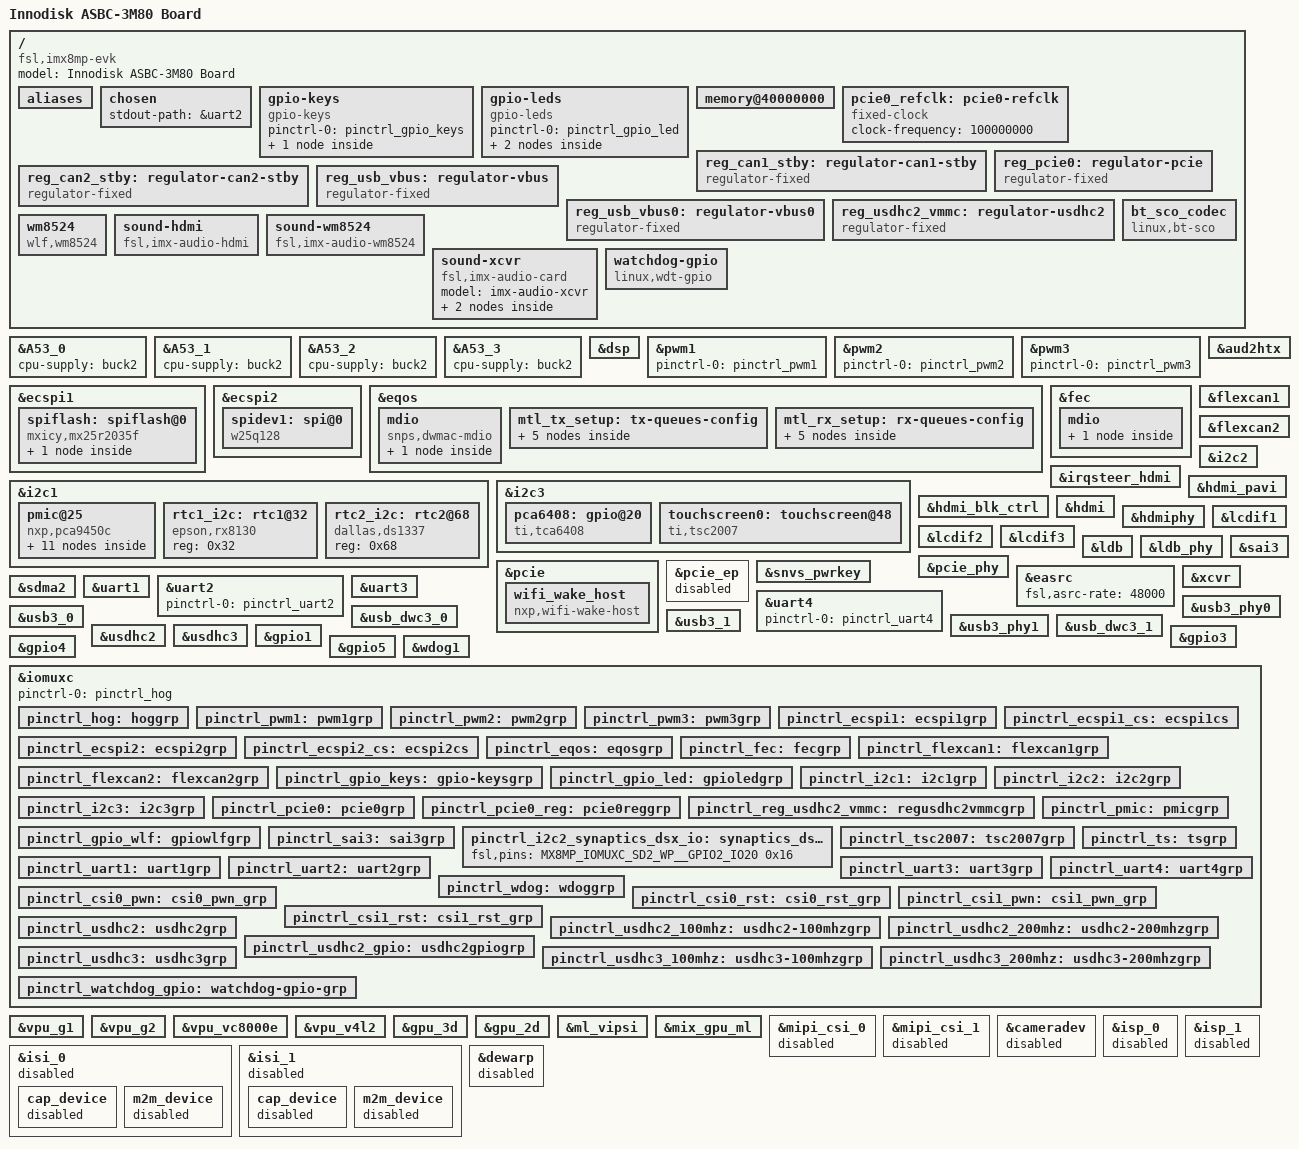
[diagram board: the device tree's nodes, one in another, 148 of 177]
// SPDX-License-Identifier: (GPL-2.0+ OR MIT)

/* Title:    Device Tree of Innodisk ASBC-3M80 Board v0.5.9
 * Author:   William Chang
 * Created:  Sep.01.2023, 09:16:15 (UTC+8)
 * Modified: May.24.2024, 15:06:37 (UTC+8)
 */

/dts-v1/;

#include <dt-bindings/phy/phy-imx8-pcie.h>
#include <dt-bindings/usb/pd.h>
#include "../freescale/imx8mp.dtsi"

/{
    model = "Innodisk ASBC-3M80 Board";
    compatible = "fsl,imx8mp-evk", "fsl,imx8mp";

    aliases {
		spi1 = &ecspi1;
		spi2 = &ecspi2;
		rtc0 = &snvs_rtc;
		rtc1 = &rtc1_i2c;
		rtc2 = &rtc2_i2c;
		pwm1 = &pwm1;
		pwm2 = &pwm2;
		pwm3 = &pwm3;
	};

    chosen {
		stdout-path = &uart2;
	};

    gpio-keys {
		compatible = "gpio-keys";
		pinctrl-names = "default";
		pinctrl-0 = <&pinctrl_gpio_keys>;

		button-user {
			label = "User Button";
			gpios = <&gpio1 7 GPIO_ACTIVE_LOW>;
			linux,code = <BTN_0>;
			wakeup-source;
		};
	};

    gpio-leds {
		compatible = "gpio-leds";
		pinctrl-names = "default";
		pinctrl-0 = <&pinctrl_gpio_led>;

		status {
			label = "yellow:status";
			gpios = <&gpio3 16 GPIO_ACTIVE_HIGH>;
			
			default-state = "on";
		};

		hdd_led {
			label = "SD/eMMC Status";
            gpios = <&gpio5 5 GPIO_ACTIVE_LOW>;
			linux,default-trigger = "mmc2";
			default-state = "off";
        };
	};

    memory@40000000 {
		device_type = "memory";
		reg = <0x0 0x40000000 0 0xc0000000>,
		      <0x1 0x00000000 0 0xc0000000>;
	};

    pcie0_refclk: pcie0-refclk {
		compatible = "fixed-clock";
		#clock-cells = <0>;
		clock-frequency = <100000000>;
	};

    reg_can1_stby: regulator-can1-stby {
		compatible = "regulator-fixed";
		regulator-name = "can1-stby";
		regulator-min-microvolt = <3300000>;
		regulator-max-microvolt = <3300000>;
		enable-active-high;
	};

    reg_can2_stby: regulator-can2-stby {
		compatible = "regulator-fixed";
		regulator-name = "can2-stby";
		regulator-min-microvolt = <3300000>;
		regulator-max-microvolt = <3300000>;
		enable-active-high;
	};

    reg_pcie0: regulator-pcie {
		compatible = "regulator-fixed";
		pinctrl-names = "default";
		pinctrl-0 = <&pinctrl_pcie0_reg>;
		regulator-name = "MPCIE_3V3";
		regulator-min-microvolt = <3300000>;
		regulator-max-microvolt = <3300000>;
		gpio = <&gpio2 2 GPIO_ACTIVE_HIGH>;
		enable-active-high;
		regulator-always-on;
	};

    reg_usb_vbus: regulator-vbus {
		compatible = "regulator-fixed";
		regulator-name = "USB_VBUS";
		regulator-min-microvolt = <5000000>;
		regulator-max-microvolt = <5000000>;
		enable-active-high;
		regulator-always-on;
	};

    reg_usb_vbus0: regulator-vbus0 {
		compatible = "regulator-fixed";
		regulator-name = "USB_VBUS_0";
		regulator-min-microvolt = <5000000>;
		regulator-max-microvolt = <5000000>;
		enable-active-high;
		regulator-always-on;
	};

    reg_usdhc2_vmmc: regulator-usdhc2 {
		compatible = "regulator-fixed";
		pinctrl-names = "default";
		pinctrl-0 = <&pinctrl_reg_usdhc2_vmmc>;
		regulator-name = "VSD_3V3";
		regulator-min-microvolt = <3300000>;
		regulator-max-microvolt = <3300000>;
		gpio = <&gpio2 19 GPIO_ACTIVE_HIGH>;
		enable-active-high;
	};

	bt_sco_codec: bt_sco_codec {
		#sound-dai-cells = <1>;
		compatible = "linux,bt-sco";
	};

    wm8524: wm8524 {
		#sound-dai-cells = <0>;
		compatible = "wlf,wm8524";
		pinctrl-names = "default";
		pinctrl-0 = <&pinctrl_gpio_wlf>;
		wlf,mute-gpios = <&gpio2 7 GPIO_ACTIVE_LOW>; /*Work only with low*/
		clocks = <&clk IMX8MP_CLK_SAI3_ROOT>;
		clock-names = "mclk";
		status = "okay";
	};

    sound-hdmi {
		compatible = "fsl,imx-audio-hdmi";
		model = "audio-hdmi";
		audio-cpu = <&aud2htx>;
		hdmi-out;
		constraint-rate = <44100>,
				<88200>,
				<176400>,
				<32000>,
				<48000>,
				<96000>,
				<192000>;
		status = "okay";
	};

    sound-wm8524 {
		compatible = "fsl,imx-audio-wm8524";
		model = "wm8524-audio";
		audio-cpu = <&sai3>;
		audio-codec = <&wm8524>;
		audio-asrc=	<&easrc>;
		audio-routing =
			"Line Out Jack", "LINEVOUTL",
			"Line Out Jack", "LINEVOUTR";
	};

    sound-xcvr {
		compatible = "fsl,imx-audio-card";
		model = "imx-audio-xcvr";
		pri-dai-link {
			link-name = "XCVR PCM";
			cpu {
				sound-dai = <&xcvr>;
			};
		};
	};

    watchdog-gpio {
		/* TPS3431 */
		pinctrl-names = "default";
		pinctrl-0 = <&pinctrl_watchdog_gpio>;
		compatible = "linux,wdt-gpio";
		// pwms = <&pwm1 0 10 0>;
		always-running;
		gpios =	<&gpio1 5 GPIO_ACTIVE_HIGH>;
		hw_algo = "toggle";
		/* Reset triggers in 2..3 seconds */
		hw_margin_ms = <200>;
		/* Disabled by default */
		status = "okay";
	};
};

&A53_0 {
	cpu-supply = <&buck2>;
};

&A53_1 {
	cpu-supply = <&buck2>;
};

&A53_2 {
	cpu-supply = <&buck2>;
};

&A53_3 {
	cpu-supply = <&buck2>;
};

&dsp {
	status = "okay";
};

&pwm1 {
	pinctrl-names = "default";
	pinctrl-0 = <&pinctrl_pwm1>;
	status = "okay";
};

&pwm2 {
	pinctrl-names = "default";
	pinctrl-0 = <&pinctrl_pwm2>;
	status = "okay";
};

&pwm3 {
	pinctrl-names = "default";
	pinctrl-0 = <&pinctrl_pwm3>;
	status = "okay";
};

&aud2htx {
	status = "okay";
};

&ecspi1 {
	pinctrl-names = "default";
	pinctrl-0 = <&pinctrl_ecspi1 &pinctrl_ecspi1_cs>;
	cs-gpios = <&gpio5 9 GPIO_ACTIVE_LOW>;
	status = "okay";

	spiflash: spiflash@0 {
		#address-cells = <1>;
		#size-cells = <1>;
		compatible = "mxicy,mx25r2035f", "jedec,spi-nor";
		spi-max-frequency = <50000000>;
		reg = <0>;
		mode = <1>;

		partition@0{
			reg = <0x0 0x100000>;
			label = "spi-flash";
		};
	};
};

&ecspi2 {
	fsl,spi-num-chipselects = <0>;
	pinctrl-names = "default";
	pinctrl-0 = <&pinctrl_ecspi2 &pinctrl_ecspi2_cs>;
	cs-gpios = <&gpio5 13 GPIO_ACTIVE_LOW>;
	status = "okay";

	spidev1: spi@0 {
		#address-cells = <1>;
		#size-cells = <0>;
		reg = <0>;
		compatible = "w25q128", "jedec,spi-nor";
		spi-max-frequency = <500000>;
		mode = <1>;
	};
};

&eqos {
	pinctrl-names = "default";
	pinctrl-0 = <&pinctrl_eqos>;
	phy-mode = "rgmii-id";
	phy-handle = <&ethphy0>;
	snps,force_thresh_dma_mode;
	snps,mtl-tx-config = <&mtl_tx_setup>;
	snps,mtl-rx-config = <&mtl_rx_setup>;
	status = "okay";

	mdio {
		compatible = "snps,dwmac-mdio";
		#address-cells = <1>;
		#size-cells = <0>;

		ethphy0: ethernet-phy@1 {
			compatible = "ethernet-phy-ieee802.3-c22";
			reg = <1>;
			eee-broken-1000t;
			reset-gpios = <&gpio4 22 GPIO_ACTIVE_LOW>;
			reset-assert-us = <10000>;
			reset-deassert-us = <80000>;
			realtek,clkout-disable;
		};
	};

	mtl_tx_setup: tx-queues-config {
		snps,tx-queues-to-use = <5>;
		snps,tx-sched-sp;

		queue0 {
			snps,dcb-algorithm;
			snps,priority = <0x1>;
		};

		queue1 {
			snps,dcb-algorithm;
			snps,priority = <0x2>;
		};

		queue2 {
			snps,dcb-algorithm;
			snps,priority = <0x4>;
		};

		queue3 {
			snps,dcb-algorithm;
			snps,priority = <0x8>;
		};

		queue4 {
			snps,dcb-algorithm;
			snps,priority = <0xf0>;
		};
	};

	mtl_rx_setup: rx-queues-config {
		snps,rx-queues-to-use = <5>;
		snps,rx-sched-sp;

		queue0 {
			snps,dcb-algorithm;
			snps,priority = <0x1>;
			snps,map-to-dma-channel = <0>;
		};

		queue1 {
			snps,dcb-algorithm;
			snps,priority = <0x2>;
			snps,map-to-dma-channel = <1>;
		};

		queue2 {
			snps,dcb-algorithm;
			snps,priority = <0x4>;
			snps,map-to-dma-channel = <2>;
		};

		queue3 {
			snps,dcb-algorithm;
			snps,priority = <0x8>;
			snps,map-to-dma-channel = <3>;
		};

		queue4 {
			snps,dcb-algorithm;
			snps,priority = <0xf0>;
			snps,map-to-dma-channel = <4>;
		};
	};
};

&fec {
	pinctrl-names = "default";
	pinctrl-0 = <&pinctrl_fec>;
	phy-mode = "rgmii-id";
	phy-handle = <&ethphy1>;
	fsl,magic-packet;
	status = "okay";

	mdio {
		#address-cells = <1>;
		#size-cells = <0>;

		ethphy1: ethernet-phy@1 {
			compatible = "ethernet-phy-ieee802.3-c22";
			reg = <1>;
			eee-broken-1000t;
			reset-gpios = <&gpio4 2 GPIO_ACTIVE_LOW>;
			reset-assert-us = <10000>;
			reset-deassert-us = <80000>;
			realtek,aldps-enable;
			realtek,clkout-disable;
		};
	};
};

&flexcan1 {
	pinctrl-names = "default";
	pinctrl-0 = <&pinctrl_flexcan1>;
	xceiver-supply = <&reg_can1_stby>;
	status = "okay";
};

&flexcan2 {
	pinctrl-names = "default";
	pinctrl-0 = <&pinctrl_flexcan2>;
	xceiver-supply = <&reg_can2_stby>;
	status = "okay";/* can2 pin conflict with pdm */
};

&i2c1 {
	clock-frequency = <400000>;
	pinctrl-names = "default";
	pinctrl-0 = <&pinctrl_i2c1>;
	status = "okay";

	pmic@25 {
		compatible = "nxp,pca9450c";
		reg = <0x25>;
		pinctrl-names = "default";
		pinctrl-0 = <&pinctrl_pmic>;
		interrupt-parent = <&gpio1>;
		interrupts = <3 IRQ_TYPE_LEVEL_LOW>;

		regulators {
			buck1: BUCK1 {
				regulator-name = "BUCK1";
				regulator-min-microvolt = <600000>;
				regulator-max-microvolt = <2187500>;
				regulator-boot-on;
				regulator-always-on;
				regulator-ramp-delay = <3125>;
			};

			buck2: BUCK2 {
				regulator-name = "BUCK2";
				regulator-min-microvolt = <600000>;
				regulator-max-microvolt = <2187500>;
				regulator-boot-on;
				regulator-always-on;
				regulator-ramp-delay = <3125>;
				nxp,dvs-run-voltage = <950000>;
				nxp,dvs-standby-voltage = <850000>;
			};

			buck4: BUCK4{
				regulator-name = "BUCK4";
				regulator-min-microvolt = <600000>;
				regulator-max-microvolt = <3400000>;
				regulator-boot-on;
				regulator-always-on;
			};

			buck5: BUCK5{
				regulator-name = "BUCK5";
				regulator-min-microvolt = <600000>;
				regulator-max-microvolt = <3400000>;
				regulator-boot-on;
				regulator-always-on;
			};

			buck6: BUCK6 {
				regulator-name = "BUCK6";
				regulator-min-microvolt = <600000>;
				regulator-max-microvolt = <3400000>;
				regulator-boot-on;
				regulator-always-on;
			};

			ldo1: LDO1 {
				regulator-name = "LDO1";
				regulator-min-microvolt = <1600000>;
				regulator-max-microvolt = <3300000>;
				regulator-boot-on;
				regulator-always-on;
			};

			ldo2: LDO2 {
				regulator-name = "LDO2";
				regulator-min-microvolt = <800000>;
				regulator-max-microvolt = <1150000>;
				regulator-boot-on;
				regulator-always-on;
			};

			ldo3: LDO3 {
				regulator-name = "LDO3";
				regulator-min-microvolt = <800000>;
				regulator-max-microvolt = <3300000>;
				regulator-boot-on;
				regulator-always-on;
			};

			ldo4: LDO4 {
				regulator-name = "LDO4";
				regulator-min-microvolt = <800000>;
				regulator-max-microvolt = <3300000>;
				regulator-boot-on;
				regulator-always-on;
			};

			ldo5: LDO5 {
				regulator-name = "LDO5";
				regulator-min-microvolt = <1800000>;
				regulator-max-microvolt = <3300000>;
				regulator-boot-on;
				regulator-always-on;
			};
		};
	};

    rtc1_i2c: rtc1@32 {
		compatible = "epson,rx8130";
		reg = <0x32>;
	};

	rtc2_i2c: rtc2@68 {
		compatible = "dallas,ds1337";
		reg = <0x68>;
	};
};

&i2c2 {
	clock-frequency = <100000>;
	pinctrl-names = "default";
	pinctrl-0 = <&pinctrl_i2c2>;
	status = "okay";
};

&i2c3 {
	clock-frequency = <400000>;
	pinctrl-names = "default";
	pinctrl-0 = <&pinctrl_i2c3>;
	status = "okay";

	pca6408: gpio@20 {
		compatible = "ti,tca6408";
		reg = <0x20>;
		gpio-controller;
		#gpio-cells = <2>;
		gpio-line-names = "I2C_GPIO0",
			"I2C_GPIO1",
			"I2C_GPIO2",
			"I2C_GPIO3",
			"I2C_GPIO4",
			"I2C_GPIO5",
			"I2C_GPIO6",
			"I2C_GPIO7";
	};

    touchscreen0: touchscreen@48 {
		compatible = "ti,tsc2007";
		reg = <0x48>;
		pinctrl-names = "default";
		pinctrl-0 = <&pinctrl_tsc2007>;
		interrupt-parent = <&gpio1>;
		interrupts = <6 IRQ_TYPE_EDGE_FALLING>;
		gpios = <&gpio1 6 GPIO_ACTIVE_LOW>;
		ti,x-plate-ohms = <500>;
		wakeup-source;
		status = "okay";
	};

    /* Uncomment this part for enabling the capacitive touch panel */

	// touchscreen1: touchscreen@2a {
	// 	compatible = "eeti,exc80h60";
	// 	pinctrl-names = "default";
	// 	pinctrl-0 = <&pinctrl_ts>;
	// 	reg = <0x2a>;
	// 	interrupt-parent = <&gpio4>;
	// 	interrupts = <0 IRQ_TYPE_EDGE_FALLING>;
	// 	reset-gpio = <&gpio4 1 GPIO_ACTIVE_LOW>;
	// 	status = "okay";
	// };
};

&irqsteer_hdmi {
	status = "okay";
};

&hdmi_blk_ctrl {
	status = "okay";
};

&hdmi_pavi {
	status = "okay";
};

&hdmi {
	status = "okay";
};

&hdmiphy {
	status = "okay";
};

&lcdif1 {
	status = "okay";
};

&lcdif2 {
	status = "okay";
};

&lcdif3 {
	status = "okay";

	thres-low  = <1 2>;             /* (FIFO * 1 / 2) */
	thres-high = <3 4>;             /* (FIFO * 3 / 4) */
};

&ldb {
	status = "okay";
};

&ldb_phy {
	status = "okay";
};

&pcie_phy {
	fsl,refclk-pad-mode = <IMX8_PCIE_REFCLK_PAD_INPUT>;
	clocks = <&pcie0_refclk>;
	clock-names = "ref";
	status = "okay";
};

&pcie {
	pinctrl-names = "default";
	pinctrl-0 = <&pinctrl_pcie0>;
	reset-gpio = <&gpio3 1 GPIO_ACTIVE_LOW>;
	clocks = <&clk IMX8MP_CLK_HSIO_ROOT>,
		 <&clk IMX8MP_CLK_PCIE_ROOT>,
		 <&clk IMX8MP_CLK_HSIO_AXI>;
	clock-names = "pcie", "pcie_aux", "pcie_bus";
	assigned-clocks = <&clk IMX8MP_CLK_PCIE_AUX>;
	assigned-clock-rates = <10000000>;
	assigned-clock-parents = <&clk IMX8MP_SYS_PLL2_50M>;
	vpcie-supply = <&reg_pcie0>;
	fsl,max-link-speed = <3>;
	status = "okay";

	wifi_wake_host {
		compatible = "nxp,wifi-wake-host";
		interrupt-parent = <&gpio5>;
		interrupts = <21 IRQ_TYPE_LEVEL_LOW>;
		interrupt-names = "host-wake";
	};
};

&pcie_ep{
	pinctrl-names = "default";
	pinctrl-0 = <&pinctrl_pcie0>;
	clocks = <&clk IMX8MP_CLK_HSIO_ROOT>,
		 <&clk IMX8MP_CLK_PCIE_ROOT>,
		 <&clk IMX8MP_CLK_HSIO_AXI>;
	clock-names = "pcie", "pcie_aux", "pcie_bus";
	assigned-clocks = <&clk IMX8MP_CLK_HSIO_AXI>,
			  <&clk IMX8MP_CLK_PCIE_AUX>;
	assigned-clock-rates = <500000000>, <10000000>;
	assigned-clock-parents = <&clk IMX8MP_SYS_PLL2_500M>,
				 <&clk IMX8MP_SYS_PLL2_50M>;
	status = "disabled";
};

&snvs_pwrkey {
	status = "okay";
};

&easrc {
	#sound-dai-cells = <0>;
	fsl,asrc-rate  = <48000>;
	status = "okay";
};

&sai3 {
	#sound-dai-cells = <0>;
	pinctrl-names = "default";
	pinctrl-0 = <&pinctrl_sai3>;
	assigned-clocks = <&clk IMX8MP_CLK_SAI3>;
	assigned-clock-parents = <&clk IMX8MP_AUDIO_PLL1_OUT>;
	assigned-clock-rates = <24576000>;
	fsl,sai-mclk-direction-output;
	fsl,sai-asynchronous;
	status = "okay";
};

&xcvr {
	#sound-dai-cells = <0>;
	status = "okay";
};

&sdma2 {
	status = "okay";
};

&uart1 {
	pinctrl-names = "default";
	pinctrl-0 = <&pinctrl_uart1>;
	assigned-clocks = <&clk IMX8MP_CLK_UART1>;
	assigned-clock-parents = <&clk IMX8MP_SYS_PLL1_80M>;
	fsl,uart-has-rtscts;
	status = "okay";
};

&uart2 {
	/* console */
	pinctrl-names = "default";
	pinctrl-0 = <&pinctrl_uart2>;
	status = "okay";
};

&uart3 {
	pinctrl-names = "default";
	pinctrl-0 = <&pinctrl_uart3>;
	assigned-clocks = <&clk IMX8MP_CLK_UART3>;
	assigned-clock-parents = <&clk IMX8MP_SYS_PLL1_80M>;
	fsl,uart-has-rtscts;
	status = "okay";
};

&uart4 {
	/* console */
	pinctrl-names = "default";
	pinctrl-0 = <&pinctrl_uart4>;
	status = "okay";
};

&usb3_phy0 {
	fsl,phy-tx-vref-tune = <0xe>;
	fsl,phy-tx-preemp-amp-tune = <3>;
	fsl,phy-tx-vboost-level = <2>;
	fsl,phy-comp-dis-tune = <7>;
	fsl,pcs-tx-deemph-3p5db = <0x21>;
	fsl,phy-pcs-tx-swing-full = <0x7f>;
	status = "okay";
};

&usb3_0 {
	status = "okay";
};

&usb_dwc3_0 {
    vbus-supply = <&reg_usb_vbus0>;
	dr_mode = "host";
	status = "okay";
};

&usb3_phy1 {
	fsl,phy-tx-preemp-amp-tune = <3>;
	fsl,phy-tx-vref-tune = <0xb>;
	fsl,phy-tx-vboost-level = <2>;
	status = "okay";
};

&usb3_1 {
	status = "okay";
};

&usb_dwc3_1 {
	vbus-supply = <&reg_usb_vbus>;
	dr_mode = "host";
	status = "okay";
};

&usdhc2 {
	assigned-clocks = <&clk IMX8MP_CLK_USDHC2>;
	assigned-clock-rates = <400000000>;
	pinctrl-names = "default", "state_100mhz", "state_200mhz";
	pinctrl-0 = <&pinctrl_usdhc2>, <&pinctrl_usdhc2_gpio>;
	pinctrl-1 = <&pinctrl_usdhc2_100mhz>, <&pinctrl_usdhc2_gpio>;
	pinctrl-2 = <&pinctrl_usdhc2_200mhz>, <&pinctrl_usdhc2_gpio>;
	cd-gpios = <&gpio2 12 GPIO_ACTIVE_LOW>;
	vmmc-supply = <&reg_usdhc2_vmmc>;
	bus-width = <4>;
	status = "okay";
};

&usdhc3 {
	assigned-clocks = <&clk IMX8MP_CLK_USDHC3>;
	assigned-clock-rates = <400000000>;
	pinctrl-names = "default", "state_100mhz", "state_200mhz";
	pinctrl-0 = <&pinctrl_usdhc3>;
	pinctrl-1 = <&pinctrl_usdhc3_100mhz>;
	pinctrl-2 = <&pinctrl_usdhc3_200mhz>;
	bus-width = <8>;
	non-removable;
	status = "okay";
};
&gpio1 {
	gpio-line-names = "WDOG_SET", "", "", "",
			  "", "WDOG_EN", "", "User_Button",
			  "EXP_GPIO3", "", "", "",
			  "", "", "EXP_GPIO8", "EXP_GPIO9",
			  "", "", "", "",
			  "", "", "", "",
			  "", "", "", "",
			  "", "", "", "";
};

&gpio3 {
	gpio-line-names = "", "", "", "",
			  "", "", "", "",
			  "", "", "", "",
			  "", "", "", "",
			  "", "", "", "",
			  "", "EXP_GPIO4", "EXP_GPIO5", "EXP_GPIO6",
			  "EXP_GPIO7", "", "", "",
			  "", "", "", "";
};

&gpio4 {
	gpio-line-names = "", "", "", "",
			  "", "", "", "",
			  "", "", "", "",
			  "", "", "", "",
			  "", "", "", "",
			  "", "", "", "EXP_GPIO2",
			  "EXP_GPIO0", "EXP_GPIO1", "", "",
			  "", "", "EXP_GPIO10", "";
};

&gpio5 {
	gpio-line-names = "", "", "", "",
			  "", "", "", "",
			  "", "", "", "",
			  "", "", "", "",
			  "", "", "", "",
			  "", "", "", "",
			  "EXP_GPIO11", "", "", "",
			  "", "", "", "";
	
	gpios = <&gpio5 24 GPIO_ACTIVE_HIGH>;
	enable-active-high;
};

&wdog1 {
	pinctrl-names = "default";
	pinctrl-0 = <&pinctrl_wdog>;
	fsl,ext-reset-output;
	status = "okay";
};

&iomuxc {
	pinctrl-names = "default";
	pinctrl-0 = <&pinctrl_hog>;
	pinctrl_hog: hoggrp {
		fsl,pins = <
			MX8MP_IOMUXC_HDMI_DDC_SCL__HDMIMIX_HDMI_SCL	0x400001c2
			MX8MP_IOMUXC_HDMI_DDC_SDA__HDMIMIX_HDMI_SDA	0x400001c2
			MX8MP_IOMUXC_HDMI_HPD__HDMIMIX_HDMI_HPD		0x40000010
			MX8MP_IOMUXC_HDMI_CEC__HDMIMIX_HDMI_CEC		0x40000010			
		>;
	};
    pinctrl_pwm1: pwm1grp {
		fsl,pins = <
			MX8MP_IOMUXC_GPIO1_IO01__PWM1_OUT	0x116
		>;
	};

	pinctrl_pwm2: pwm2grp {
		fsl,pins = <
			MX8MP_IOMUXC_GPIO1_IO09__PWM2_OUT		0x116
		>;
	};

    pinctrl_pwm3: pwm3grp {
		fsl,pins = <
			MX8MP_IOMUXC_GPIO1_IO10__PWM3_OUT		0x116
		>;
	};

    pinctrl_ecspi1: ecspi1grp {
		fsl,pins = <
			MX8MP_IOMUXC_ECSPI1_SCLK__ECSPI1_SCLK		0x10
			MX8MP_IOMUXC_ECSPI1_MOSI__ECSPI1_MOSI		0x10
			MX8MP_IOMUXC_ECSPI1_MISO__ECSPI1_MISO		0x10
		>;
	};

	pinctrl_ecspi1_cs: ecspi1cs {
		fsl,pins = <
			MX8MP_IOMUXC_ECSPI1_SS0__GPIO5_IO09			0x10
		>;
	};

	pinctrl_ecspi2: ecspi2grp {
		fsl,pins = <
			MX8MP_IOMUXC_ECSPI2_SCLK__ECSPI2_SCLK		0x82
			MX8MP_IOMUXC_ECSPI2_MOSI__ECSPI2_MOSI		0x82
			MX8MP_IOMUXC_ECSPI2_MISO__ECSPI2_MISO		0x82
		>;
	};

	pinctrl_ecspi2_cs: ecspi2cs {
		fsl,pins = <
			MX8MP_IOMUXC_ECSPI2_SS0__GPIO5_IO13		0x40000
		>;
	};

    pinctrl_eqos: eqosgrp {
		fsl,pins = <
			MX8MP_IOMUXC_ENET_MDC__ENET_QOS_MDC				0x2
			MX8MP_IOMUXC_ENET_MDIO__ENET_QOS_MDIO				0x2
			MX8MP_IOMUXC_ENET_RD0__ENET_QOS_RGMII_RD0			0x90
			MX8MP_IOMUXC_ENET_RD1__ENET_QOS_RGMII_RD1			0x90
			MX8MP_IOMUXC_ENET_RD2__ENET_QOS_RGMII_RD2			0x90
			MX8MP_IOMUXC_ENET_RD3__ENET_QOS_RGMII_RD3			0x90
			MX8MP_IOMUXC_ENET_RXC__CCM_ENET_QOS_CLOCK_GENERATE_RX_CLK	0x90
			MX8MP_IOMUXC_ENET_RX_CTL__ENET_QOS_RGMII_RX_CTL			0x90
			MX8MP_IOMUXC_ENET_TD0__ENET_QOS_RGMII_TD0			0x16
			MX8MP_IOMUXC_ENET_TD1__ENET_QOS_RGMII_TD1			0x16
			MX8MP_IOMUXC_ENET_TD2__ENET_QOS_RGMII_TD2			0x16
			MX8MP_IOMUXC_ENET_TD3__ENET_QOS_RGMII_TD3			0x16
			MX8MP_IOMUXC_ENET_TX_CTL__ENET_QOS_RGMII_TX_CTL			0x16
			MX8MP_IOMUXC_ENET_TXC__CCM_ENET_QOS_CLOCK_GENERATE_TX_CLK	0x16
			MX8MP_IOMUXC_SAI2_RXC__GPIO4_IO22				0x10
		>;
	};

	pinctrl_fec: fecgrp {
		fsl,pins = <
			MX8MP_IOMUXC_SAI1_RXD2__ENET1_MDC		0x2
			MX8MP_IOMUXC_SAI1_RXD3__ENET1_MDIO		0x2
			MX8MP_IOMUXC_SAI1_RXD4__ENET1_RGMII_RD0		0x90
			MX8MP_IOMUXC_SAI1_RXD5__ENET1_RGMII_RD1		0x90
			MX8MP_IOMUXC_SAI1_RXD6__ENET1_RGMII_RD2		0x90
			MX8MP_IOMUXC_SAI1_RXD7__ENET1_RGMII_RD3		0x90
			MX8MP_IOMUXC_SAI1_TXC__ENET1_RGMII_RXC		0x90
			MX8MP_IOMUXC_SAI1_TXFS__ENET1_RGMII_RX_CTL	0x90
			MX8MP_IOMUXC_SAI1_TXD0__ENET1_RGMII_TD0		0x16
			MX8MP_IOMUXC_SAI1_TXD1__ENET1_RGMII_TD1		0x16
			MX8MP_IOMUXC_SAI1_TXD2__ENET1_RGMII_TD2		0x16
			MX8MP_IOMUXC_SAI1_TXD3__ENET1_RGMII_TD3		0x16
			MX8MP_IOMUXC_SAI1_TXD4__ENET1_RGMII_TX_CTL	0x16
			MX8MP_IOMUXC_SAI1_TXD5__ENET1_RGMII_TXC		0x16
			MX8MP_IOMUXC_SAI1_RXD0__GPIO4_IO02		0x10
		>;
	};

    pinctrl_flexcan1: flexcan1grp {
		fsl,pins = <
			MX8MP_IOMUXC_SPDIF_RX__CAN1_RX          0x154
			MX8MP_IOMUXC_SPDIF_TX__CAN1_TX          0x154
		>;
	};

    pinctrl_flexcan2: flexcan2grp {
		fsl,pins = <
			MX8MP_IOMUXC_SAI2_TXD0__CAN2_TX        		0x154
			MX8MP_IOMUXC_SAI2_MCLK__CAN2_RX        		0x154
		>;
	};

    pinctrl_gpio_keys: gpio-keysgrp {
		fsl,pins = <
			MX8MP_IOMUXC_GPIO1_IO07__GPIO1_IO07 		0x140
		>;
	};

    pinctrl_gpio_led: gpioledgrp {
		fsl,pins = <
			MX8MP_IOMUXC_NAND_READY_B__GPIO3_IO16	0x140
		>;
	};

    pinctrl_i2c1: i2c1grp {
		fsl,pins = <
			MX8MP_IOMUXC_I2C1_SCL__I2C1_SCL		0x400001c2
			MX8MP_IOMUXC_I2C1_SDA__I2C1_SDA		0x400001c2
		>;
	};

	pinctrl_i2c2: i2c2grp {
		fsl,pins = <
			MX8MP_IOMUXC_I2C2_SCL__I2C2_SCL		0x400001c2
			MX8MP_IOMUXC_I2C2_SDA__I2C2_SDA		0x400001c2
		>;
	};

	pinctrl_i2c3: i2c3grp {
		fsl,pins = <
			MX8MP_IOMUXC_I2C3_SCL__I2C3_SCL		0x400001c2
			MX8MP_IOMUXC_I2C3_SDA__I2C3_SDA		0x400001c2
		>;
	};

    pinctrl_pcie0: pcie0grp {
		fsl,pins = <
			MX8MP_IOMUXC_I2C4_SCL__PCIE_CLKREQ_B	0x60 /* open drain, pull up */
            MX8MP_IOMUXC_NAND_CE0_B__GPIO3_IO01		0x1c0
			MX8MP_IOMUXC_I2C4_SDA__GPIO5_IO21		0x1c4
		>;
	};

    pinctrl_pcie0_reg: pcie0reggrp {
		fsl,pins = <
			MX8MP_IOMUXC_SD1_DATA0__GPIO2_IO02	0x40
		>;
	};

    pinctrl_reg_usdhc2_vmmc: regusdhc2vmmcgrp {
		fsl,pins = <
			MX8MP_IOMUXC_SD2_RESET_B__GPIO2_IO19	0x40
		>;
	};

    pinctrl_pmic: pmicgrp {
		fsl,pins = <
			MX8MP_IOMUXC_GPIO1_IO03__GPIO1_IO03	0x000001c0
		>;
	};

	pinctrl_gpio_wlf: gpiowlfgrp {
		fsl,pins = <
			MX8MP_IOMUXC_SD1_DATA5__GPIO2_IO07				0xd6
		>;
	};

    pinctrl_sai3: sai3grp {
		fsl,pins = <
			MX8MP_IOMUXC_SAI3_TXFS__AUDIOMIX_SAI3_TX_SYNC	0xd6
			MX8MP_IOMUXC_SAI3_TXC__AUDIOMIX_SAI3_TX_BCLK	0xd6
			MX8MP_IOMUXC_SAI3_TXD__AUDIOMIX_SAI3_TX_DATA00	0xd6
			MX8MP_IOMUXC_SAI3_MCLK__AUDIOMIX_SAI3_MCLK		0xd6
		>;
	};

    pinctrl_i2c2_synaptics_dsx_io: synaptics_dsx_iogrp {
		fsl,pins = <
			MX8MP_IOMUXC_SD2_WP__GPIO2_IO20		0x16
		>;
	};

	pinctrl_tsc2007: tsc2007grp {
		fsl,pins = <
		MX8MP_IOMUXC_GPIO1_IO06__GPIO1_IO06 0x10 /* Interrupt */
		>;
  	};

	pinctrl_ts: tsgrp {
		fsl,pins = <
			MX8MP_IOMUXC_SAI1_RXFS__GPIO4_IO00		0x16
			MX8MP_IOMUXC_SAI1_RXC__GPIO4_IO01 		0x10
		>;
	};

    pinctrl_uart1: uart1grp {
		fsl,pins = <
			MX8MP_IOMUXC_UART1_RXD__UART1_DCE_RX	0x140
			MX8MP_IOMUXC_UART1_TXD__UART1_DCE_TX	0x140
			MX8MP_IOMUXC_UART3_RXD__UART1_DCE_CTS	0x140
			MX8MP_IOMUXC_UART3_TXD__UART1_DCE_RTS	0x140
		>;
	};

	pinctrl_uart2: uart2grp {
		fsl,pins = <
			MX8MP_IOMUXC_SD1_DATA3__UART2_DCE_RX	0x140
			MX8MP_IOMUXC_SD1_DATA2__UART2_DCE_TX	0x140
		>;
	};

	pinctrl_uart3: uart3grp {
		fsl,pins = <
			MX8MP_IOMUXC_SD1_DATA6__UART3_DCE_TX		0x140
			MX8MP_IOMUXC_SD1_DATA7__UART3_DCE_RX 		0x140
			MX8MP_IOMUXC_SD1_RESET_B__UART3_DCE_RTS		0x140
			MX8MP_IOMUXC_SD1_STROBE__UART3_DCE_CTS		0x140
		>;
	};

    pinctrl_uart4: uart4grp {
		fsl,pins = <
			MX8MP_IOMUXC_UART4_RXD__UART4_DCE_RX	0x140
			MX8MP_IOMUXC_UART4_TXD__UART4_DCE_TX	0x140
		>;
	};

	pinctrl_wdog: wdoggrp {
		fsl,pins = <
			MX8MP_IOMUXC_GPIO1_IO02__WDOG1_WDOG_B	0x166
		>;
	};
	
	pinctrl_csi0_pwn: csi0_pwn_grp {
		fsl,pins = <
			MX8MP_IOMUXC_SAI1_TXD6__GPIO4_IO18		0x10
		>;
	};

	pinctrl_csi0_rst: csi0_rst_grp {
		fsl,pins = <	
			MX8MP_IOMUXC_SAI1_TXD7__GPIO4_IO19		0x10
		>;
	};

	pinctrl_csi1_pwn: csi1_pwn_grp {
		fsl,pins = <
			MX8MP_IOMUXC_SAI3_RXFS__GPIO4_IO28		0x10
		>;
	};

	pinctrl_csi1_rst: csi1_rst_grp {
		fsl,pins = <
			MX8MP_IOMUXC_SAI3_RXC__GPIO4_IO29		0x10
		>;
	};

    pinctrl_usdhc2: usdhc2grp {
		fsl,pins = <
			MX8MP_IOMUXC_SD2_CLK__USDHC2_CLK	0x190
			MX8MP_IOMUXC_SD2_CMD__USDHC2_CMD	0x1d0
			MX8MP_IOMUXC_SD2_DATA0__USDHC2_DATA0	0x1d0
			MX8MP_IOMUXC_SD2_DATA1__USDHC2_DATA1	0x1d0
			MX8MP_IOMUXC_SD2_DATA2__USDHC2_DATA2	0x1d0
			MX8MP_IOMUXC_SD2_DATA3__USDHC2_DATA3	0x1d0
			MX8MP_IOMUXC_GPIO1_IO04__USDHC2_VSELECT	0xc0
		>;
	};

	pinctrl_usdhc2_100mhz: usdhc2-100mhzgrp {
		fsl,pins = <
			MX8MP_IOMUXC_SD2_CLK__USDHC2_CLK	0x194
			MX8MP_IOMUXC_SD2_CMD__USDHC2_CMD	0x1d4
			MX8MP_IOMUXC_SD2_DATA0__USDHC2_DATA0	0x1d4
			MX8MP_IOMUXC_SD2_DATA1__USDHC2_DATA1	0x1d4
			MX8MP_IOMUXC_SD2_DATA2__USDHC2_DATA2	0x1d4
			MX8MP_IOMUXC_SD2_DATA3__USDHC2_DATA3	0x1d4
			MX8MP_IOMUXC_GPIO1_IO04__USDHC2_VSELECT 0xc0
		>;
	};

	pinctrl_usdhc2_200mhz: usdhc2-200mhzgrp {
		fsl,pins = <
			MX8MP_IOMUXC_SD2_CLK__USDHC2_CLK	0x196
			MX8MP_IOMUXC_SD2_CMD__USDHC2_CMD	0x1d6
			MX8MP_IOMUXC_SD2_DATA0__USDHC2_DATA0	0x1d6
			MX8MP_IOMUXC_SD2_DATA1__USDHC2_DATA1	0x1d6
			MX8MP_IOMUXC_SD2_DATA2__USDHC2_DATA2	0x1d6
			MX8MP_IOMUXC_SD2_DATA3__USDHC2_DATA3	0x1d6
			MX8MP_IOMUXC_GPIO1_IO04__USDHC2_VSELECT 0xc0
		>;
	};

	pinctrl_usdhc2_gpio: usdhc2gpiogrp {
		fsl,pins = <
			MX8MP_IOMUXC_SD2_CD_B__GPIO2_IO12	0x1c4
		>;
	};

	pinctrl_usdhc3: usdhc3grp {
		fsl,pins = <
			MX8MP_IOMUXC_NAND_WE_B__USDHC3_CLK	0x190
			MX8MP_IOMUXC_NAND_WP_B__USDHC3_CMD	0x1d0
			MX8MP_IOMUXC_NAND_DATA04__USDHC3_DATA0	0x1d0
			MX8MP_IOMUXC_NAND_DATA05__USDHC3_DATA1	0x1d0
			MX8MP_IOMUXC_NAND_DATA06__USDHC3_DATA2	0x1d0
			MX8MP_IOMUXC_NAND_DATA07__USDHC3_DATA3	0x1d0
			MX8MP_IOMUXC_NAND_RE_B__USDHC3_DATA4	0x1d0
			MX8MP_IOMUXC_NAND_CE2_B__USDHC3_DATA5	0x1d0
			MX8MP_IOMUXC_NAND_CE3_B__USDHC3_DATA6	0x1d0
			MX8MP_IOMUXC_NAND_CLE__USDHC3_DATA7	0x1d0
			MX8MP_IOMUXC_NAND_CE1_B__USDHC3_STROBE	0x190
		>;
	};

	pinctrl_usdhc3_100mhz: usdhc3-100mhzgrp {
		fsl,pins = <
			MX8MP_IOMUXC_NAND_WE_B__USDHC3_CLK	0x194
			MX8MP_IOMUXC_NAND_WP_B__USDHC3_CMD	0x1d4
			MX8MP_IOMUXC_NAND_DATA04__USDHC3_DATA0	0x1d4
			MX8MP_IOMUXC_NAND_DATA05__USDHC3_DATA1	0x1d4
			MX8MP_IOMUXC_NAND_DATA06__USDHC3_DATA2	0x1d4
			MX8MP_IOMUXC_NAND_DATA07__USDHC3_DATA3	0x1d4
			MX8MP_IOMUXC_NAND_RE_B__USDHC3_DATA4	0x1d4
			MX8MP_IOMUXC_NAND_CE2_B__USDHC3_DATA5	0x1d4
			MX8MP_IOMUXC_NAND_CE3_B__USDHC3_DATA6	0x1d4
			MX8MP_IOMUXC_NAND_CLE__USDHC3_DATA7	0x1d4
			MX8MP_IOMUXC_NAND_CE1_B__USDHC3_STROBE	0x194
		>;
	};

	pinctrl_usdhc3_200mhz: usdhc3-200mhzgrp {
		fsl,pins = <
			MX8MP_IOMUXC_NAND_WE_B__USDHC3_CLK	0x196
			MX8MP_IOMUXC_NAND_WP_B__USDHC3_CMD	0x1d6
			MX8MP_IOMUXC_NAND_DATA04__USDHC3_DATA0	0x1d6
			MX8MP_IOMUXC_NAND_DATA05__USDHC3_DATA1	0x1d6
			MX8MP_IOMUXC_NAND_DATA06__USDHC3_DATA2	0x1d6
			MX8MP_IOMUXC_NAND_DATA07__USDHC3_DATA3	0x1d6
			MX8MP_IOMUXC_NAND_RE_B__USDHC3_DATA4	0x1d6
			MX8MP_IOMUXC_NAND_CE2_B__USDHC3_DATA5	0x1d6
			MX8MP_IOMUXC_NAND_CE3_B__USDHC3_DATA6	0x1d6
			MX8MP_IOMUXC_NAND_CLE__USDHC3_DATA7	0x1d6
			MX8MP_IOMUXC_NAND_CE1_B__USDHC3_STROBE	0x196
		>;
	};

    pinctrl_watchdog_gpio: watchdog-gpio-grp {
		fsl,pins = <
			/* WDOG_B# */
			MX8MP_IOMUXC_GPIO1_IO02__WDOG1_WDOG_B		0x26
			/* WDOG_EN */
			MX8MP_IOMUXC_GPIO1_IO05__GPIO1_IO05			0x16
			/* WDOG_SET -- ungate WDT RESET# signal propagation */
			MX8MP_IOMUXC_GPIO1_IO00__GPIO1_IO00			0x16
			/* WDOG_PWM
			MX8MP_IOMUXC_GPIO1_IO01__PWM1_OUT			0x116*/
		>;
	};
};

&vpu_g1 {
	status = "okay";
};

&vpu_g2 {
	status = "okay";
};

&vpu_vc8000e {
	status = "okay";
};

&vpu_v4l2 {
	status = "okay";
};

&gpu_3d {
	status = "okay";
};

&gpu_2d {
	status = "okay";
};

&ml_vipsi {
	status = "okay";
};

&mix_gpu_ml {
	status = "okay";
};

&mipi_csi_0 {
	status = "disabled";
};

&mipi_csi_1 {
	status = "disabled";
};

&cameradev {
	status = "disabled";
};

&isi_0 {
	status = "disabled";

	cap_device {
		status = "disabled";
	};

	m2m_device {
		status = "disabled";
	};
};

&isi_1 {
	status = "disabled";

	cap_device {
		status = "disabled";
	};

	m2m_device {
		status = "disabled";
	};
};

&isp_0 {
	status = "disabled";
};

&isp_1 {
	status = "disabled";
};

&dewarp {
	status = "disabled";
};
